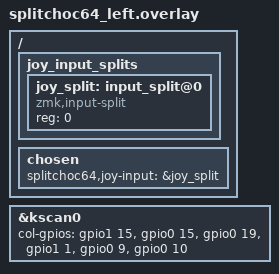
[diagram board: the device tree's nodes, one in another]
#include "splitchoc64.dtsi"

&kscan0 {
    /* LEFT Ver012: COL0..5 = D10,D11,D12,D13,D14,D15 */
    col-gpios
        = <&gpio1 15 GPIO_ACTIVE_HIGH>
        , <&gpio0 15 GPIO_ACTIVE_HIGH>
        , <&gpio0 19 GPIO_ACTIVE_HIGH>
        , <&gpio1 1 GPIO_ACTIVE_HIGH>
        , <&gpio0 9 GPIO_ACTIVE_HIGH>
        , <&gpio0 10 GPIO_ACTIVE_HIGH>
        ;
};

/ {
    /* Native ZMK split-input proxy. No HID code runs on the right peripheral. */
    joy_input_splits {
        #address-cells = <1>;
        #size-cells = <0>;

        joy_split: input_split@0 {
            compatible = "zmk,input-split";
            reg = <0>;
        };
    };



    chosen {
        splitchoc64,joy-input = &joy_split;
    };
};
